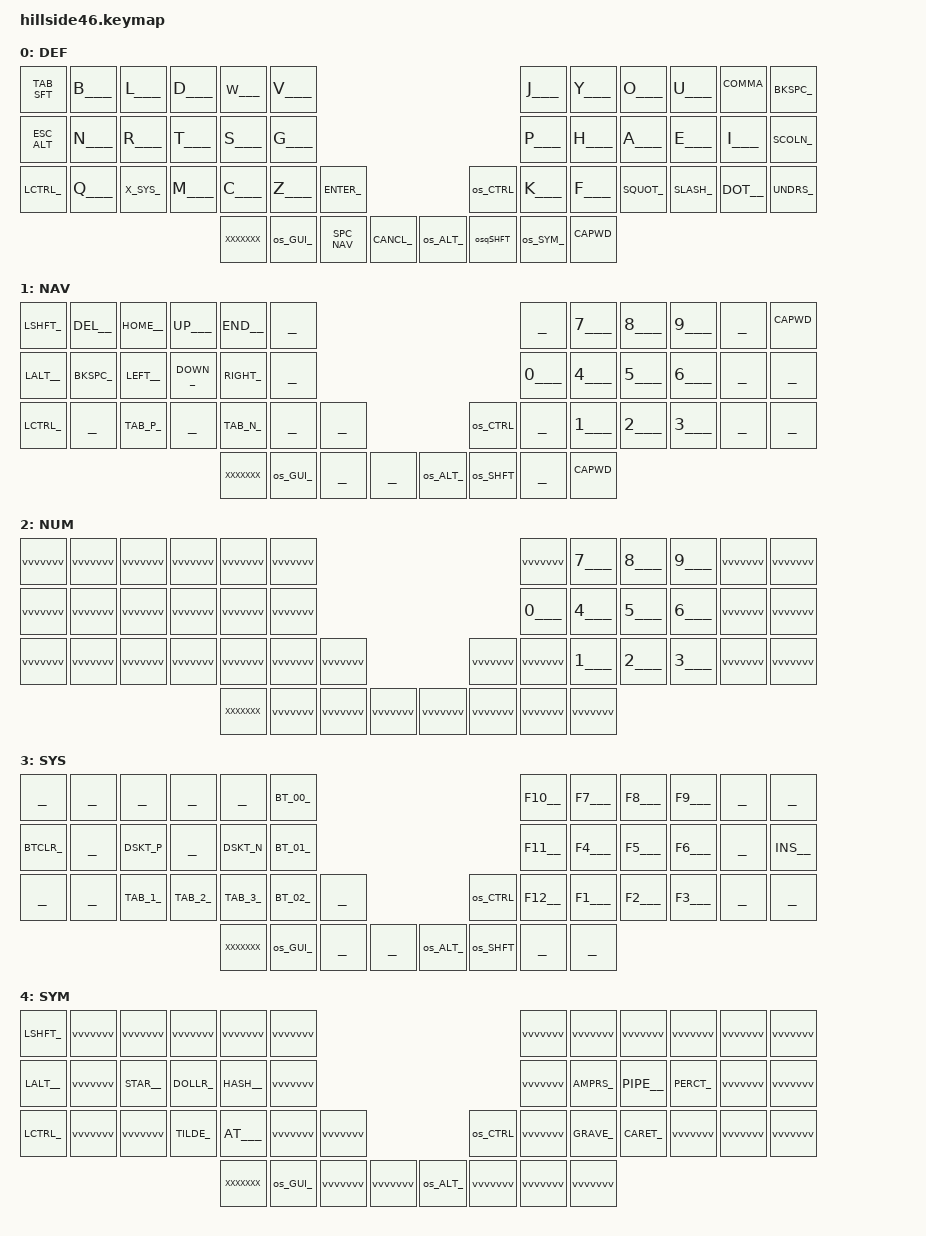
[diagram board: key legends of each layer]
#include <behaviors.dtsi>
#include <dt-bindings/zmk/keys.h>
#include <dt-bindings/zmk/bt.h>
#include "keycodes.h"

// LAYERS
#define DEF 0
#define NAV 1
#define NUM 2
#define SYS 3
#define SYM 4

#include "macros.dtsi"
#include "combos.dtsi"
#include "mod_morph.dtsi"

&sk {
    // One Shot Mod
    release-after-ms = <6000>;
};
&sl {
    // One Shot Layer
    release-after-ms = <2500>;
};

/ {
    behaviors {
      // Sticky Key with Quick Release
      skq: sticky_key_quick_release {
        compatible = "zmk,behavior-sticky-key";
        label = "STICKY_KEY_QUICK_RELEASE";
        #binding-cells = <1>;
        bindings = <&kp>;
        release-after-ms = <2000>;
        quick-release;
      };

      bht: balanced_hold_tap {
          compatible = "zmk,behavior-hold-tap";
          label = "balanced_hold_tap";
          #binding-cells = <2>;
          tapping-term-ms = <200>;    // <---[[moderate duration]]
          quick-tap-ms = <0>;
          flavor = "balanced";
          bindings = <&kp>, <&kp>;
      };
    };
};

/ {
  
  keymap {
    
    compatible = "zmk,keymap";

    // Hands Down Neu
    // base_layer {
    //   label = "DEF";
    //   bindings = <
    //     TAB_SFT  ___W___  ___F___  ___M___  ___P___  ___V___                                      _MINUS_  __DOT__  _BKSPC_  _SCOLN_  ___K___  _SLASH_
    //     ESC_ALT  ___R___  ___S___  ___N___  ___T___  ___B___                                      _COMMA_  ___A___  ___E___  ___I___  ___H___  ___J___
    //     _LCTRL_  _X_SYS_  ___C___  ___L___  ___D___  ___G___  _ENTER_                    os_CTRL  _EQUAL_  ___U___  ___O___  ___Y___  _SQUOT_  _UNDRS_
    //                                         XXXXXXX  os_GUI_  SPC_NAV  _CANCL_  os_ALT_  osqSHFT  os_SYM_  _CAPWD_
    //   >;
    //   sensor-bindings = <&inc_dec_kp LC(Y) LC(E)>;
    // };

    // Gallium V1
    base_layer {
      label = "DEF";
      bindings = <
        TAB_SFT  ___B___  ___L___  ___D___  ___W___  ___V___                                      ___J___  ___Y___  ___O___  ___U___  _COMMA_  _BKSPC_
        ESC_ALT  ___N___  ___R___  ___T___  ___S___  ___G___                                      ___P___  ___H___  ___A___  ___E___  ___I___  _SCOLN_
        _LCTRL_  ___Q___  _X_SYS_  ___M___  ___C___  ___Z___  _ENTER_                    os_CTRL  ___K___  ___F___  _SQUOT_  _SLASH_  __DOT__  _UNDRS_
                                            XXXXXXX  os_GUI_  SPC_NAV  _CANCL_  os_ALT_  osqSHFT  os_SYM_  _CAPWD_
      >;
      sensor-bindings = <&inc_dec_kp LC(Y) LC(E)>;
    };

    nav_layer {
      label = "NAV";
      bindings = <
        _LSHFT_  __DEL__  _HOME__  __UP___  __END__  _______                                      _______  ___7___  ___8___  ___9___  _______  _CAPWD_    
        _LALT__  _BKSPC_  _LEFT__  _DOWN__  _RIGHT_  _______                                      ___0___  ___4___  ___5___  ___6___  _______  _______    
        _LCTRL_  _______  _TAB_P_  _______  _TAB_N_  _______  _______                    os_CTRL  _______  ___1___  ___2___  ___3___  _______  _______    
                                            XXXXXXX  os_GUI_  _______  _______  os_ALT_  os_SHFT  _______  _CAPWD_            
      >;
    };

    num_layer {
      label = "NUM";
      bindings = <
        vvvvvvv  vvvvvvv  vvvvvvv  vvvvvvv  vvvvvvv  vvvvvvv                                      vvvvvvv  ___7___  ___8___  ___9___  vvvvvvv  vvvvvvv
        vvvvvvv  vvvvvvv  vvvvvvv  vvvvvvv  vvvvvvv  vvvvvvv                                      ___0___  ___4___  ___5___  ___6___  vvvvvvv  vvvvvvv
        vvvvvvv  vvvvvvv  vvvvvvv  vvvvvvv  vvvvvvv  vvvvvvv  vvvvvvv                    vvvvvvv  vvvvvvv  ___1___  ___2___  ___3___  vvvvvvv  vvvvvvv
                                            XXXXXXX  vvvvvvv  vvvvvvv  vvvvvvv  vvvvvvv  vvvvvvv  vvvvvvv  vvvvvvv                
      >;
    };

    sys_layer {
      label = "SYS";
      bindings = <
        _______  _______  _______  _______  _______  _BT_00_                                      __F10__  __F7___  __F8___  __F9___  _______  _______
        _BTCLR_  _______  _DSKT_P  _______  _DSKT_N  _BT_01_                                      __F11__  __F4___  __F5___  __F6___  _______  __INS__
        _______  _______  _TAB_1_  _TAB_2_  _TAB_3_  _BT_02_  _______                    os_CTRL  __F12__  __F1___  __F2___  __F3___  _______  _______
                                            XXXXXXX  os_GUI_  _______  _______  os_ALT_  os_SHFT  _______  _______                
      >;
    };

    sym_layer {
      label = "SYM";
      bindings = <
        _LSHFT_  vvvvvvv  vvvvvvv  vvvvvvv  vvvvvvv  vvvvvvv                                      vvvvvvv  vvvvvvv  vvvvvvv  vvvvvvv  vvvvvvv  vvvvvvv
        _LALT__  vvvvvvv  _STAR__  _DOLLR_  _HASH__  vvvvvvv                                      vvvvvvv  _AMPRS_  _PIPE__  _PERCT_  vvvvvvv  vvvvvvv
        _LCTRL_  vvvvvvv  vvvvvvv  _TILDE_  __AT___  vvvvvvv  vvvvvvv                    os_CTRL  vvvvvvv  _GRAVE_  _CARET_  vvvvvvv  vvvvvvv  vvvvvvv
                                            XXXXXXX  os_GUI_  vvvvvvv  vvvvvvv  os_ALT_  vvvvvvv  vvvvvvv  vvvvvvv                 
      >;
    };

  };
};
